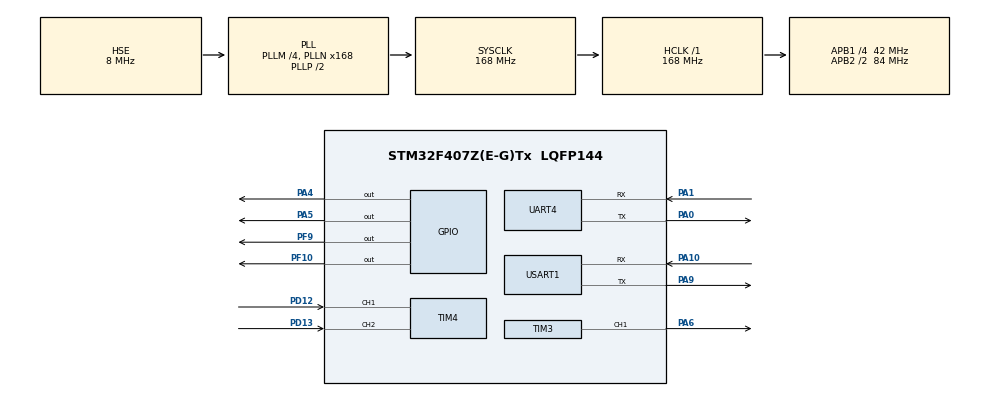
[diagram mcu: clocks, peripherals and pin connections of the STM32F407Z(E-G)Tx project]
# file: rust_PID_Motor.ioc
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Dma.Request0=USART1_TX
Dma.Request1=USART1_RX
Dma.USART1_RX.1.Direction=DMA_PERIPH_TO_MEMORY
Dma.USART1_RX.1.FIFOMode=DMA_FIFOMODE_DISABLE
Dma.USART1_RX.1.Instance=DMA2_Stream2
Dma.USART1_RX.1.MemDataAlignment=DMA_MDATAALIGN_BYTE
Dma.USART1_RX.1.MemInc=DMA_MINC_ENABLE
Dma.USART1_RX.1.Mode=DMA_NORMAL
Dma.USART1_RX.1.PeriphDataAlignment=DMA_PDATAALIGN_BYTE
Dma.USART1_RX.1.PeriphInc=DMA_PINC_DISABLE
Dma.USART1_RX.1.Priority=DMA_PRIORITY_MEDIUM
Dma.USART1_TX.0.Direction=DMA_MEMORY_TO_PERIPH
Dma.USART1_TX.0.FIFOMode=DMA_FIFOMODE_DISABLE
Dma.USART1_TX.0.Instance=DMA2_Stream7
Dma.USART1_TX.0.MemDataAlignment=DMA_MDATAALIGN_BYTE
Dma.USART1_TX.0.MemInc=DMA_MINC_ENABLE
Dma.USART1_TX.0.Mode=DMA_NORMAL
Dma.USART1_TX.0.PeriphDataAlignment=DMA_PDATAALIGN_BYTE
Dma.USART1_TX.0.PeriphInc=DMA_PINC_DISABLE
Dma.USART1_TX.0.Priority=DMA_PRIORITY_HIGH
Mcu.Family=STM32F4
Mcu.Name=STM32F407Z(E-G)Tx
Mcu.Package=LQFP144
NVIC.DMA2_Stream2_IRQn=true\:0\:0\:false\:false\:true\:false\:true\:true
NVIC.DMA2_Stream7_IRQn=true\:0\:0\:false\:false\:true\:false\:true\:true
NVIC.PriorityGroup=NVIC_PRIORITYGROUP_4
NVIC.UART4_IRQn=true\:0\:0\:false\:false\:true\:true\:true\:true
NVIC.USART1_IRQn=true\:0\:0\:false\:false\:true\:true\:true\:true
PA0-WKUP.Mode=Asynchronous
PA0-WKUP.Signal=UART4_TX
PA1.Mode=Asynchronous
PA1.Signal=UART4_RX
PA10.Mode=Asynchronous
PA10.Signal=USART1_RX
PA13.Mode=Serial_Wire
PA13.Signal=SYS_JTMS-SWDIO
PA14.Mode=Serial_Wire
PA14.Signal=SYS_JTCK-SWCLK
PA4.Signal=GPIO_Output
PA5.Signal=GPIO_Output
PA6.Signal=S_TIM3_CH1
PA9.Mode=Asynchronous
PA9.Signal=USART1_TX
PD12.Signal=S_TIM4_CH1
PD13.Signal=S_TIM4_CH2
PF10.Signal=GPIO_Output
PF9.Signal=GPIO_Output
PH0-OSC_IN.Mode=HSE-External-Oscillator
PH0-OSC_IN.Signal=RCC_OSC_IN
PH1-OSC_OUT.Mode=HSE-External-Oscillator
PH1-OSC_OUT.Signal=RCC_OSC_OUT
ProjectManager.HeapSize=0x200
ProjectManager.StackSize=0x400
ProjectManager.TargetToolchain=CMake
RCC.48MHZClocksFreq_Value=84000000
RCC.AHBFreq_Value=168000000
RCC.APB1CLKDivider=RCC_HCLK_DIV4
RCC.APB1Freq_Value=42000000
RCC.APB1TimFreq_Value=84000000
RCC.APB2CLKDivider=RCC_HCLK_DIV2
RCC.APB2Freq_Value=84000000
RCC.APB2TimFreq_Value=168000000
RCC.CortexFreq_Value=168000000
RCC.HCLKFreq_Value=168000000
RCC.HSE_VALUE=8000000
RCC.HSI_VALUE=16000000
RCC.LSE_VALUE=32768
RCC.PLLM=4
RCC.PLLN=168
RCC.PLLSourceVirtual=RCC_PLLSOURCE_HSE
RCC.SYSCLKFreq_VALUE=168000000
RCC.SYSCLKSource=RCC_SYSCLKSOURCE_PLLCLK
RCC.VCOOutputFreq_Value=336000000
SH.S_TIM3_CH1.0=TIM3_CH1,PWM Generation1 CH1
SH.S_TIM4_CH1.0=TIM4_CH1,Encoder_Interface
SH.S_TIM4_CH2.0=TIM4_CH2,Encoder_Interface
TIM3.AutoReloadPreload=TIM_AUTORELOAD_PRELOAD_ENABLE
TIM3.Channel-PWM\ Generation1\ CH1=TIM_CHANNEL_1
TIM3.OCFastMode_PWM-PWM\ Generation1\ CH1=TIM_OCFAST_ENABLE
TIM3.Period=1000
TIM3.Prescaler=83
TIM4.EncoderMode=TIM_ENCODERMODE_TI12
UART4.VirtualMode=Asynchronous
USART1.VirtualMode=VM_ASYNC
VP_TIM3_VS_ClockSourceINT.Mode=Internal
board=custom

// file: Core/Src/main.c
/* USER CODE BEGIN Header */
/**
  ******************************************************************************
  * @file           : main.c
  * @brief          : Main program body
  ******************************************************************************
  * @attention
  *
  * Copyright (c) 2026 STMicroelectronics.
  * All rights reserved.
  *
  * This software is licensed under terms that can be found in the LICENSE file
  * in the root directory of this software component.
  * If no LICENSE file comes with this software, it is provided AS-IS.
  *
  ******************************************************************************
  */
/* USER CODE END Header */
#include "main.h"

TIM_HandleTypeDef htim3;
TIM_HandleTypeDef htim4;

UART_HandleTypeDef huart4;
UART_HandleTypeDef huart1;
DMA_HandleTypeDef hdma_usart1_tx;
DMA_HandleTypeDef hdma_usart1_rx;

void SystemClock_Config(void);
static void MX_GPIO_Init(void);
static void MX_DMA_Init(void);
static void MX_USART1_UART_Init(void);
static void MX_TIM4_Init(void);
static void MX_TIM3_Init(void);
static void MX_UART4_Init(void);

int main(void)
{

  /* MCU Configuration--------------------------------------------------------*/

  /* Reset of all peripherals, Initializes the Flash interface and the Systick. */
  HAL_Init();

  /* Configure the system clock */
  SystemClock_Config();

  /* Initialize all configured peripherals */
  MX_GPIO_Init();
  MX_DMA_Init();
  MX_USART1_UART_Init();
  MX_TIM4_Init();
  MX_TIM3_Init();
  MX_UART4_Init();
  /* USER CODE BEGIN 2 */
  rust_run();
  /* USER CODE END 2 */

  /* Infinite loop */
  while (1)
  {

  }
}

void SystemClock_Config(void)
{
  RCC_OscInitTypeDef RCC_OscInitStruct = {0};
  RCC_ClkInitTypeDef RCC_ClkInitStruct = {0};

  /** Configure the main internal regulator output voltage
  */
  __HAL_RCC_PWR_CLK_ENABLE();
  __HAL_PWR_VOLTAGESCALING_CONFIG(PWR_REGULATOR_VOLTAGE_SCALE1);

  /** Initializes the RCC Oscillators according to the specified parameters
  * in the RCC_OscInitTypeDef structure.
  */
  RCC_OscInitStruct.OscillatorType = RCC_OSCILLATORTYPE_HSE;
  RCC_OscInitStruct.HSEState = RCC_HSE_ON;
  RCC_OscInitStruct.PLL.PLLState = RCC_PLL_ON;
  RCC_OscInitStruct.PLL.PLLSource = RCC_PLLSOURCE_HSE;
  RCC_OscInitStruct.PLL.PLLM = 4;
  RCC_OscInitStruct.PLL.PLLN = 168;
  RCC_OscInitStruct.PLL.PLLP = RCC_PLLP_DIV2;
  RCC_OscInitStruct.PLL.PLLQ = 4;
  if (HAL_RCC_OscConfig(&RCC_OscInitStruct) != HAL_OK)
  {
    Error_Handler();
  }

  /** Initializes the CPU, AHB and APB buses clocks
  */
  RCC_ClkInitStruct.ClockType = RCC_CLOCKTYPE_HCLK|RCC_CLOCKTYPE_SYSCLK
                              |RCC_CLOCKTYPE_PCLK1|RCC_CLOCKTYPE_PCLK2;
  RCC_ClkInitStruct.SYSCLKSource = RCC_SYSCLKSOURCE_PLLCLK;
  RCC_ClkInitStruct.AHBCLKDivider = RCC_SYSCLK_DIV1;
  RCC_ClkInitStruct.APB1CLKDivider = RCC_HCLK_DIV4;
  RCC_ClkInitStruct.APB2CLKDivider = RCC_HCLK_DIV2;

  if (HAL_RCC_ClockConfig(&RCC_ClkInitStruct, FLASH_LATENCY_5) != HAL_OK)
  {
    Error_Handler();
  }
}

static void MX_TIM3_Init(void)
{

  TIM_ClockConfigTypeDef sClockSourceConfig = {0};
  TIM_MasterConfigTypeDef sMasterConfig = {0};
  TIM_OC_InitTypeDef sConfigOC = {0};

  htim3.Instance = TIM3;
  htim3.Init.Prescaler = 83;
  htim3.Init.CounterMode = TIM_COUNTERMODE_UP;
  htim3.Init.Period = 1000;
  htim3.Init.ClockDivision = TIM_CLOCKDIVISION_DIV1;
  htim3.Init.AutoReloadPreload = TIM_AUTORELOAD_PRELOAD_ENABLE;
  if (HAL_TIM_Base_Init(&htim3) != HAL_OK)
  {
    Error_Handler();
  }
  sClockSourceConfig.ClockSource = TIM_CLOCKSOURCE_INTERNAL;
  if (HAL_TIM_ConfigClockSource(&htim3, &sClockSourceConfig) != HAL_OK)
  {
    Error_Handler();
  }
  if (HAL_TIM_PWM_Init(&htim3) != HAL_OK)
  {
    Error_Handler();
  }
  sMasterConfig.MasterOutputTrigger = TIM_TRGO_RESET;
  sMasterConfig.MasterSlaveMode = TIM_MASTERSLAVEMODE_DISABLE;
  if (HAL_TIMEx_MasterConfigSynchronization(&htim3, &sMasterConfig) != HAL_OK)
  {
    Error_Handler();
  }
  sConfigOC.OCMode = TIM_OCMODE_PWM1;
  sConfigOC.Pulse = 0;
  sConfigOC.OCPolarity = TIM_OCPOLARITY_HIGH;
  sConfigOC.OCFastMode = TIM_OCFAST_ENABLE;
  if (HAL_TIM_PWM_ConfigChannel(&htim3, &sConfigOC, TIM_CHANNEL_1) != HAL_OK)
  {
    Error_Handler();
  }
  HAL_TIM_MspPostInit(&htim3);

}

static void MX_TIM4_Init(void)
{

  TIM_Encoder_InitTypeDef sConfig = {0};
  TIM_MasterConfigTypeDef sMasterConfig = {0};

  htim4.Instance = TIM4;
  htim4.Init.Prescaler = 0;
  htim4.Init.CounterMode = TIM_COUNTERMODE_UP;
  htim4.Init.Period = 65535;
  htim4.Init.ClockDivision = TIM_CLOCKDIVISION_DIV1;
  htim4.Init.AutoReloadPreload = TIM_AUTORELOAD_PRELOAD_DISABLE;
  sConfig.EncoderMode = TIM_ENCODERMODE_TI12;
  sConfig.IC1Polarity = TIM_ICPOLARITY_RISING;
  sConfig.IC1Selection = TIM_ICSELECTION_DIRECTTI;
  sConfig.IC1Prescaler = TIM_ICPSC_DIV1;
  sConfig.IC1Filter = 0;
  sConfig.IC2Polarity = TIM_ICPOLARITY_RISING;
  sConfig.IC2Selection = TIM_ICSELECTION_DIRECTTI;
  sConfig.IC2Prescaler = TIM_ICPSC_DIV1;
  sConfig.IC2Filter = 0;
  if (HAL_TIM_Encoder_Init(&htim4, &sConfig) != HAL_OK)
  {
    Error_Handler();
  }
  sMasterConfig.MasterOutputTrigger = TIM_TRGO_RESET;
  sMasterConfig.MasterSlaveMode = TIM_MASTERSLAVEMODE_DISABLE;
  if (HAL_TIMEx_MasterConfigSynchronization(&htim4, &sMasterConfig) != HAL_OK)
  {
    Error_Handler();
  }

}

static void MX_UART4_Init(void)
{

  huart4.Instance = UART4;
  huart4.Init.BaudRate = 115200;
  huart4.Init.WordLength = UART_WORDLENGTH_8B;
  huart4.Init.StopBits = UART_STOPBITS_1;
  huart4.Init.Parity = UART_PARITY_NONE;
  huart4.Init.Mode = UART_MODE_TX_RX;
  huart4.Init.HwFlowCtl = UART_HWCONTROL_NONE;
  huart4.Init.OverSampling = UART_OVERSAMPLING_16;
  if (HAL_UART_Init(&huart4) != HAL_OK)
  {
    Error_Handler();
  }

}

static void MX_USART1_UART_Init(void)
{

  huart1.Instance = USART1;
  huart1.Init.BaudRate = 115200;
  huart1.Init.WordLength = UART_WORDLENGTH_8B;
  huart1.Init.StopBits = UART_STOPBITS_1;
  huart1.Init.Parity = UART_PARITY_NONE;
  huart1.Init.Mode = UART_MODE_TX_RX;
  huart1.Init.HwFlowCtl = UART_HWCONTROL_NONE;
  huart1.Init.OverSampling = UART_OVERSAMPLING_16;
  if (HAL_UART_Init(&huart1) != HAL_OK)
  {
    Error_Handler();
  }

}

static void MX_DMA_Init(void)
{

  /* DMA controller clock enable */
  __HAL_RCC_DMA2_CLK_ENABLE();

  /* DMA interrupt init */
  /* DMA2_Stream2_IRQn interrupt configuration */
  HAL_NVIC_SetPriority(DMA2_Stream2_IRQn, 0, 0);
  HAL_NVIC_EnableIRQ(DMA2_Stream2_IRQn);
  /* DMA2_Stream7_IRQn interrupt configuration */
  HAL_NVIC_SetPriority(DMA2_Stream7_IRQn, 0, 0);
  HAL_NVIC_EnableIRQ(DMA2_Stream7_IRQn);

}

static void MX_GPIO_Init(void)
{
  GPIO_InitTypeDef GPIO_InitStruct = {0};

  /* GPIO Ports Clock Enable */
  __HAL_RCC_GPIOF_CLK_ENABLE();
  __HAL_RCC_GPIOH_CLK_ENABLE();
  __HAL_RCC_GPIOA_CLK_ENABLE();
  __HAL_RCC_GPIOD_CLK_ENABLE();

  /*Configure GPIO pin Output Level */
  HAL_GPIO_WritePin(GPIOF, GPIO_PIN_9|GPIO_PIN_10, GPIO_PIN_RESET);

  /*Configure GPIO pin Output Level */
  HAL_GPIO_WritePin(GPIOA, GPIO_PIN_4|GPIO_PIN_5, GPIO_PIN_RESET);

  /*Configure GPIO pins : PF9 PF10 */
  GPIO_InitStruct.Pin = GPIO_PIN_9|GPIO_PIN_10;
  GPIO_InitStruct.Mode = GPIO_MODE_OUTPUT_PP;
  GPIO_InitStruct.Pull = GPIO_NOPULL;
  GPIO_InitStruct.Speed = GPIO_SPEED_FREQ_LOW;
  HAL_GPIO_Init(GPIOF, &GPIO_InitStruct);

  /*Configure GPIO pins : PA4 PA5 */
  GPIO_InitStruct.Pin = GPIO_PIN_4|GPIO_PIN_5;
  GPIO_InitStruct.Mode = GPIO_MODE_OUTPUT_PP;
  GPIO_InitStruct.Pull = GPIO_NOPULL;
  GPIO_InitStruct.Speed = GPIO_SPEED_FREQ_LOW;
  HAL_GPIO_Init(GPIOA, &GPIO_InitStruct);

}

void Error_Handler(void)
{
  __disable_irq();
  while (1)
  {
  }
}
